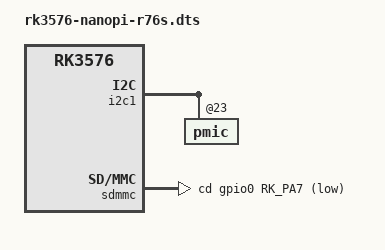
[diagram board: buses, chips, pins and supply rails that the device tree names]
// SPDX-License-Identifier: (GPL-2.0+ OR MIT)

/dts-v1/;

#include <rockchip/rk3576-nanopi-r76s.dts>
#include "rk3576-patch.dtsi"
#include "rk3576-ip.dtsi"
#include "rk3576-ip-rk806.dtsi"

/ {
	eth_order = "0001:21:00.0,0000:01:00.0";
};

&i2c1 {
	pmic@23 {
		/* 0: restart PMU;
		 * 1: reset all the power off reset registers,
		 *    forcing the state to switch to ACTIVE mode;
		 * 2: Reset all the power off reset registers,
		 *    forcing the state to switch to ACTIVE mode,
		 *    and simultaneously pull down the RESETB PIN for 5mS before releasing
		 */
		// pmic-reset-func = <1>;
		rockchip,reset-mode = <1>;
	};
};

/*
&pcie0 {
    rockchip,irq-affinity = <0xf0>;
};

&pcie1 {
    rockchip,irq-affinity = <0xf0>;
};
*/

/*
 * HS400ES + CQE. The FORESEE A3A551 eMMC needs the FriendlyElec
 * 6.1.141 BSP RK3576 tap values from 037-09; do not reintroduce the
 * mainline CVE-2025-71200 low-clock rejection without re-testing.
 */
&sdhci {
	mmc-hs400-1_8v;
	mmc-hs400-enhanced-strobe;
};

&sdmmc {
	cd-gpios = <&gpio0 RK_PA7 GPIO_ACTIVE_LOW>;
};
